VERSION ""

NS_ :

BS_:

BU_: EGT4 Fueltech

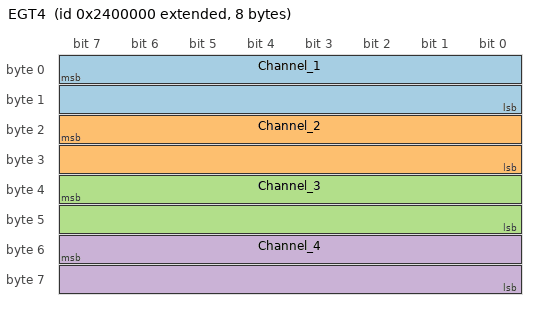
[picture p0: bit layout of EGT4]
BO_ 2185232384 EGT4: 8 EGT4
 SG_ Channel_1 : 7|16@0- (0.125,0) [-50|1050] "degC" Vector
 SG_ Channel_2 : 23|16@0- (0.125,0) [-50|1050] "degC" Vector
 SG_ Channel_3 : 39|16@0- (0.125,0) [-50|1050] "degC" Vector
 SG_ Channel_4 : 55|16@0- (0.125,0) [-50|1050] "degC" Vector

BA_DEF_ BO_  "VFrameFormat" ENUM  "StandardCAN","ExtendedCAN","reserved","J1939PG";
BA_DEF_DEF_  "VFrameFormat" "ExtendedCAN";
